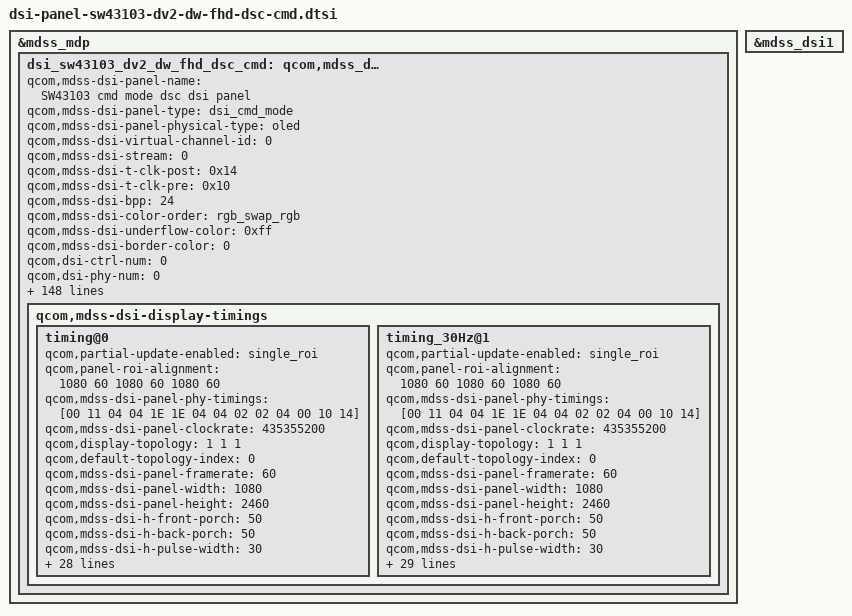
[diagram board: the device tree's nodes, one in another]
/* Copyright (c) 2014, Code Aurora Forum. All rights reserved.
 *
 * This program is free software; you can redistribute it and/or modify
 * it under the terms of the GNU General Public License version 2 and
 * only version 2 as published by the Free Software Foundation.
 *
 * This program is distributed in the hope that it will be useful,
 * but WITHOUT ANY WARRANTY; without even the implied warranty of
 * MERCHANTABILITY or FITNESS FOR A PARTICULAR PURPOSE.  See the
 * GNU General Public License for more details.
 */

&mdss_mdp {
    dsi_sw43103_dv2_dw_fhd_dsc_cmd: qcom,mdss_dsi_sw43103_dv2_dw_fhd_dsc_cmd {
		qcom,mdss-dsi-panel-name = "SW43103 cmd mode dsc dsi panel";
		qcom,mdss-dsi-panel-type = "dsi_cmd_mode";
		qcom,mdss-dsi-panel-physical-type = "oled";
		qcom,mdss-dsi-virtual-channel-id = <0>;
		qcom,mdss-dsi-stream = <0>;
		qcom,mdss-dsi-t-clk-post = <0x14>;
		qcom,mdss-dsi-t-clk-pre = <0x10>;
		qcom,mdss-dsi-bpp = <24>;
		qcom,mdss-dsi-color-order = "rgb_swap_rgb";
		qcom,mdss-dsi-underflow-color = <0xff>;
		qcom,mdss-dsi-border-color = <0>;
		qcom,dsi-ctrl-num = <0>;
		qcom,dsi-phy-num = <0>;
		qcom,dsi-select-clocks = "mux_byte_clk0", "mux_pixel_clk0";
		qcom,mdss-dsi-traffic-mode = "burst_mode";
		qcom,mdss-dsi-lane-map = "lane_map_0123";
		qcom,mdss-dsi-bllp-eof-power-mode;
		qcom,mdss-dsi-bllp-power-mode;
		qcom,mdss-dsi-lane-0-state;
		qcom,mdss-dsi-lane-1-state;
		qcom,mdss-dsi-lane-2-state;
		qcom,mdss-dsi-lane-3-state;
		qcom,mdss-dsi-reset-sequence = <1 10>, <0 2>, <1 10>;
		qcom,mdss-dsi-dma-trigger = "trigger_sw";
		qcom,mdss-dsi-mdp-trigger = "none";
		qcom,mdss-dsi-te-pin-select = <1>;
		qcom,panel-te-source = <0>;
		qcom,mdss-dsi-wr-mem-start = <0x2c>;
		qcom,mdss-dsi-wr-mem-continue = <0x3c>;
		qcom,mdss-dsi-te-dcs-command = <1>;
		qcom,mdss-dsi-lp11-init;
		qcom,mdss-dsi-tx-eot-append;
		qcom,ulps-enabled;
		//qcom,null-insertion-enabled;

		qcom,mdss-dsi-panel-hdr-enabled;
		qcom,mdss-dsi-panel-hdr-color-primaries = <14880 15935 32435 16555 14945 30910 7790 3415>;
		qcom,mdss-dsi-panel-peak-brightness = <5000000>;		/* max. 500nits */
		qcom,mdss-dsi-panel-blackness-level = <6134>;

		qcom,mdss-pan-physical-width-dimension = <69>;
		qcom,mdss-pan-physical-height-dimension = <158>;

		//lge,use-dim-ctrl;
		/* Brightness Map List */
		lge,blmap-daylight = <
			0
			5 5 5 5 5 5 5 5 5 5 6 7 9 10 11 12 14 15 16 17
			19 20 21 22 23 25 26 27 28 30 31 32 33 35 36 37 38 40 41 42
			43 45 46 47 49 50 51 52 54 55 56 57 59 60 61 63 64 65 66 68
			69 74 78 83 87 92 97 101 106 110 115 119 124 129 133 138 142 147 152 156
			161 165 170 175 179 184 189 193 198 203 208 212 217 222 227 232 236 241 246 251
			256 260 265 270 275 279 284 289 297 304 312 320 327 335 343 350 358 366 373 381
			389 396 404 412 419 427 435 442 450 458 465 473 481 489 496 504 512 520 528 536
			544 552 560 568 576 584 592 600 608 616 624 632 640 648 656 664 672 680 688 701
			714 726 739 752 765 777 790 803 816 828 841 854 867 880 892 905 918 931 943 956
			969 982 995 1007 1020 1033 1046 1058 1071 1084 1097 1109 1122 1135 1148 1161 1173 1186 1199 1212
			1224 1237 1250 1263 1275 1288 1301 1310 1320 1329 1339 1348 1357 1367 1376 1385 1395 1404 1414 1423
			1432 1442 1451 1460 1470 1479 1489 1498 1507 1517 1526 1536 1546 1556 1566 1576 1586 1597 1607 1617
			1627 1637 1648 1658 1668 1678 1688 1699 1709 1719 1729 1739 1750 1760 1770 1773 1775 1778 1780 1783
			1785 1788 1790 1793 1795 1798 1800 1803 1805 1808 1810 1813 1815 1818 1820 1823 1825 1828 1830 1833
			1835 1838 1841 1843 1846 1848 1851 1853 1856 1858 1861 1863 1866 1868 1871 1873 1876 1878 1881 1883
			1886 1888 1891 1893 1896 1898 1901 1903 1906 1909 1911 1914 1916 1919 1921 1924 1926 1929 1931 1934
			1936 1939 1941 1944 1946 1949 1951 1954 1956 1959 1961 1964 1966 1969 1971 1974 1976 1979 1982 1984
			1987 1989 1992 1994 1997 1999 2002 2004 2007 2009 2012 2014 2017 2019 2022 2024 2027 2029 2032 2034
			2037 2039 2042 2044 2047
		>;
		lge,blmap-ve = <
			0
			5 5 5 5 5 5 5 5 5 5 6 7 9 10 11 12 14 15 16 17
			19 20 21 22 23 25 26 27 28 30 31 32 33 35 36 37 38 40 41 42
			43 45 46 47 49 50 51 52 54 55 56 57 59 60 61 63 64 65 66 68
			69 74 78 83 87 92 97 101 106 110 115 119 124 129 133 138 142 147 152 156
			161 165 170 175 179 184 189 193 198 203 208 212 217 222 227 232 236 241 246 251
			256 260 265 270 275 279 284 289 297 304 312 320 327 335 343 350 358 366 373 381
			389 396 404 412 419 427 435 442 450 458 465 473 481 489 496 504 512 520 528 536
			544 552 560 568 576 584 592 600 608 616 624 632 640 648 656 664 672 680 688 701
			714 726 739 752 765 777 790 803 816 828 841 854 867 880 892 905 918 931 943 956
			969 982 995 1007 1020 1033 1046 1058 1071 1084 1097 1109 1122 1135 1148 1161 1173 1186 1199 1212
			1224 1237 1250 1263 1275 1288 1301 1310 1320 1329 1339 1348 1357 1367 1376 1385 1395 1404 1414 1423
			1432 1442 1451 1460 1470 1479 1489 1498 1507 1517 1526 1536 1546 1556 1566 1576 1586 1597 1607 1617
			1627 1637 1648 1658 1668 1678 1688 1699 1709 1719 1729 1739 1750 1760 1770 1773 1775 1778 1780 1783
			1785 1788 1790 1793 1795 1798 1800 1803 1805 1808 1810 1813 1815 1818 1820 1823 1825 1828 1830 1833
			1835 1838 1841 1843 1846 1848 1851 1853 1856 1858 1861 1863 1866 1868 1871 1873 1876 1878 1881 1883
			1886 1888 1891 1893 1896 1898 1901 1903 1906 1909 1911 1914 1916 1919 1921 1924 1926 1929 1931 1934
			1936 1939 1941 1944 1946 1949 1951 1954 1956 1959 1961 1964 1966 1969 1971 1974 1976 1979 1982 1984
			1987 1989 1992 1994 1997 1999 2002 2004 2007 2009 2012 2014 2017 2019 2022 2024 2027 2029 2032 2034
			2037 2039 2042 2044 2047
		>;
		lge,blmap-ex = <
			0
			16 16 16 16 16 16 16 16 16 25 35 44 53 62 72 81 90 99 109 118
			127 136 146 155 164 173 183 192 201 210 220 229 238 247 257 266 273 281 288 295
			303 310 317 325 332 339 347 354 361 369 376 383 391 398 405 413 420 427 435 442
			449 457 464 471 479 486 493 501 508 515 523 530 537 545 552 572 592 612 632 652
			672 692 712 732 752 772 792 812 832 852 872 892 912 932 952 972 992 1009 1026 1043
			1060 1076 1093 1110 1127 1144 1161 1178 1195 1212 1228 1245 1262 1279 1296 1310 1325 1339 1353 1368
			1382 1396 1411 1425 1439 1453 1468 1482 1496 1511 1525 1539 1554 1568 1568 1568 1568 1568 1568 1568
			1589 1611 1632 1653 1674 1696 1717 1738 1759 1781 1802 1823 1844 1866 1887 1908 1929 1951 1972 1972
			1972 1972 1972 1972 1972 1972 1972 1972 1972 1972 1972 1972 1972 1972 1972 1972 1972 1972 1972 1972
			1972 1972 1972 1972 1972 1972 1972 1972 1972 1972 1972 1972 1972 1972 1972 1972 1972 1972 1972 1972
			1972 1972 1972 1972 1972 1972 1972 1972 1972 1972 1972 1972 1972 1972 1972 1972 1972 1972 1972 1972
			1972 1972 1972 1972 1972 1972 1972 1972 1972 1972 1972 1972 1972 1972 1972 1972 1972 1972 1972 1972
			1972 1972 1972 1972 1972 1972 1972 1972 1972 1972 1972 1972 1972 1972 1972
		>;
		lge,blmap-hdr-daylight = <
			0
			5 5 5 5 5 5 5 5 5 5 6 7 9 10 11 12 14 15 16 17
			19 20 21 22 23 25 26 27 28 30 31 32 33 35 36 37 38 40 41 42
			43 45 46 47 49 50 51 52 54 55 56 57 59 60 61 63 64 65 66 68
			69 74 78 83 87 92 97 101 106 110 115 119 124 129 133 138 142 147 152 156
			161 165 170 175 179 184 189 193 198 203 208 212 217 222 227 232 236 241 246 251
			256 260 265 270 275 279 284 289 297 304 312 320 327 335 343 350 358 366 373 381
			389 396 404 412 419 427 435 442 450 458 465 473 481 489 496 504 512 520 528 536
			544 552 560 568 576 584 592 600 608 616 624 632 640 648 656 664 672 680 688 701
			714 726 739 752 765 777 790 803 816 828 841 854 867 880 892 905 918 931 943 956
			969 982 995 1007 1020 1033 1046 1058 1071 1084 1097 1109 1122 1135 1148 1161 1173 1186 1199 1212
			1224 1237 1250 1263 1275 1288 1301 1310 1320 1329 1339 1348 1357 1367 1376 1385 1395 1404 1414 1423
			1432 1442 1451 1460 1470 1479 1489 1498 1507 1517 1526 1536 1546 1556 1566 1576 1586 1597 1607 1617
			1627 1637 1648 1658 1668 1678 1688 1699 1709 1719 1729 1739 1750 1760 1770 1773 1775 1778 1780 1783
			1785 1788 1790 1793 1795 1798 1800 1803 1805 1808 1810 1813 1815 1818 1820 1823 1825 1828 1830 1833
			1835 1838 1841 1843 1846 1848 1851 1853 1856 1858 1861 1863 1866 1868 1871 1873 1876 1878 1881 1883
			1886 1888 1891 1893 1896 1898 1901 1903 1906 1909 1911 1914 1916 1919 1921 1924 1926 1929 1931 1934
			1936 1939 1941 1944 1946 1949 1951 1954 1956 1959 1961 1964 1966 1969 1971 1974 1976 1979 1982 1984
			1987 1989 1992 1994 1997 1999 2002 2004 2007 2009 2012 2014 2017 2019 2022 2024 2027 2029 2032 2034
			2037 2039 2042 2044 2047
		>;
		lge,blmap = <
			0
			5 5 5 5 5 5 5 5 5 5 6 7 8 9 10 11 12 13 14 15
			16 17 18 19 20 21 22 23 24 25 26 27 28 29 30 31 32 33 34 35
			36 37 38 39 40 41 42 43 45 46 47 48 49 50 51 52 53 54 55 56
			57 61 65 68 72 76 80 83 87 91 95 98 102 106 110 113 117 121 125 128
			132 136 140 144 147 151 155 159 163 167 170 174 178 182 186 190 194 198 202 206
			210 214 217 221 225 229 233 237 243 250 256 263 269 276 282 289 295 302 308 315
			321 327 334 340 347 353 360 366 373 379 386 392 399 405 412 418 425 432 439 445
			452 459 465 472 479 485 492 499 506 512 519 526 532 539 546 553 559 566 573 583
			594 604 615 625 636 646 657 667 677 688 698 709 719 730 740 750 761 771 782 792
			803 813 824 834 844 855 865 876 886 897 907 917 928 938 949 959 970 980 991 1001
			1011 1022 1032 1043 1053 1064 1074 1083 1093 1102 1111 1121 1130 1139 1149 1158 1167 1177 1186 1195
			1205 1214 1223 1233 1242 1251 1261 1270 1279 1289 1298 1308 1318 1328 1338 1348 1358 1368 1379 1389
			1399 1409 1419 1429 1439 1450 1460 1470 1480 1490 1500 1511 1521 1531 1541 1546 1550 1555 1559 1564
			1569 1573 1578 1582 1587 1592 1596 1601 1605 1610 1615 1619 1624 1628 1633 1638 1642 1647 1651 1656
			1661 1665 1670 1674 1679 1684 1688 1693 1697 1702 1707 1711 1716 1720 1725 1730 1734 1739 1743 1748
			1753 1757 1762 1766 1771 1776 1780 1785 1789 1794 1799 1803 1808 1812 1817 1822 1826 1831 1835 1840
			1845 1849 1854 1858 1863 1868 1872 1877 1881 1886 1891 1895 1900 1904 1909 1914 1918 1923 1927 1932
			1937 1941 1946 1950 1955 1960 1964 1969 1973 1978 1983 1987 1992 1996 2001 2006 2010 2015 2019 2024
			2029 2033 2038 2042 2047
		>;
		lge,blmap-hdr = <
			0
			5 5 5 5 5 5 5 5 5 5 6 7 8 9 10 11 12 13 14 15
			16 17 18 19 20 21 22 23 24 25 26 27 28 29 30 31 32 33 34 35
			36 37 38 39 40 41 42 43 45 46 47 48 49 50 51 52 53 54 55 56
			57 61 65 68 72 76 80 83 87 91 95 98 102 106 110 113 117 121 125 128
			132 136 140 144 147 151 155 159 163 167 170 174 178 182 186 190 194 198 202 206
			210 214 217 221 225 229 233 237 243 250 256 263 269 276 282 289 295 302 308 315
			321 327 334 340 347 353 360 366 373 379 386 392 399 405 412 418 425 432 439 445
			452 459 465 472 479 485 492 499 506 512 519 526 532 539 546 553 559 566 573 583
			594 604 615 625 636 646 657 667 677 688 698 709 719 730 740 750 761 771 782 792
			803 813 824 834 844 855 865 876 886 897 907 917 928 938 949 959 970 980 991 1001
			1011 1022 1032 1043 1053 1064 1074 1083 1093 1102 1111 1121 1130 1139 1149 1158 1167 1177 1186 1195
			1205 1214 1223 1233 1242 1251 1261 1270 1279 1289 1298 1308 1318 1328 1338 1348 1358 1368 1379 1389
			1399 1409 1419 1429 1439 1450 1460 1470 1480 1490 1500 1511 1521 1531 1541 1546 1550 1555 1559 1564
			1569 1573 1578 1582 1587 1592 1596 1601 1605 1610 1615 1619 1624 1628 1633 1638 1642 1647 1651 1656
			1661 1665 1670 1674 1679 1684 1688 1693 1697 1702 1707 1711 1716 1720 1725 1730 1734 1739 1743 1748
			1753 1757 1762 1766 1771 1776 1780 1785 1789 1794 1799 1803 1808 1812 1817 1822 1826 1831 1835 1840
			1845 1849 1854 1858 1863 1868 1872 1877 1881 1886 1891 1895 1900 1904 1909 1914 1918 1923 1927 1932
			1937 1941 1946 1950 1955 1960 1964 1969 1973 1978 1983 1987 1992 1996 2001 2006 2010 2015 2019 2024
			2029 2033 2038 2042 2047
		>;

		lge,mdss-dsi-nolp-command = [
			15 01 00 00 28 00 02 53 84
			39 01 00 00 00 00 02 B0 A1
			39 01 00 00 3C 00 12 C1 88 C8 60 0F 51 50 50 34 4F 5A 33 06 54 54 11 11 02 // AVDD 6.7V change
			05 01 00 00 00 00 01 13
			15 01 00 00 00 00 02 B0 CA
		];
		lge,mdss-dsi-nolp-command-state = "dsi_lp_mode";
		lge,mdss-dsi-lp2-command = [
			15 01 00 00 14 00 02 53 00
			39 01 00 00 00 00 02 B0 A1
			39 01 00 00 3C 00 12 C1 88 C8 60 0F 51 50 50 34 4F 5A 33 06 54 54 08 11 02 // AVDD 5.8V change
			05 01 00 00 00 00 01 12
			15 01 00 00 00 00 02 B0 CA
		];
		lge,mdss-dsi-lp2-command-state = "dsi_lp_mode";

		lge,use-vr-lp-mode;
		lge,mdss-dsi-vr-lp-mode-on-command = [
			15 01 00 00 00 00 02 B0 A3
			39 01 00 00 00 00 08 B5 00 0B 00 3B 00 3B 10
			15 01 00 00 00 00 02 B0 CA
		];
		lge,mdss-dsi-vr-lp-mode-off-command = [
			15 01 00 00 00 00 02 B0 A3
			39 01 00 00 00 00 08 B5 00 3B 00 3B 00 3B 10
			15 01 00 00 00 00 02 B0 CA
		];
		lge,mdss-dsi-vr-lp-command-state = "dsi_lp_mode";
		lge,blmap-vr = < 0 165 >;

		lge,use-color-manager;
		lge,use-color-manager-oled;
		lge,color-manager-default-status = <1>;
		lge,mdss-dsi-color-manager-mode-table = <0 1>, <1 1>, <2 1>, <3 1>;
		lge,digital-gamma-absent;

		/* FP LHBM */
		lge,use-fp-lhbm;
		lge,use-fps-mode1-new;
		lge,mdss-dsi-fp-lhbm-ready-command = [
			15 01 00 00 00 00 02 53 A4
			39 00 00 00 00 00 03 51 05 53
			15 00 00 00 00 00 02 B0 A3
			39 00 00 00 00 00 1F B6 90 00 A1 80 F7 AA 90 00 A1 63 60 41 45 0D 94 26 BD E4 27 61 40 18 05 9C 08 A9 F8 09 A1 00
			15 01 00 00 00 00 02 B0 CA
		];
		lge,mdss-dsi-fp-lhbm-ready-command-state = "dsi_hs_mode";

		lge,mdss-dsi-fp-lhbm-exit-command = [
			15 01 00 00 00 00 02 53 84
			15 00 00 00 00 00 02 B0 A3
			39 00 00 00 00 00 1F B6 90 00 A1 80 F7 AA 71 B0 F1 63 60 41 45 0D 94 26 BD E4 27 61 40 18 05 9C 08 A9 F8 09 A1 00
			15 01 00 00 00 00 02 B0 CA
		];
		lge,mdss-dsi-fp-lhbm-exit-command-state = "dsi_hs_mode";

		lge,mdss-dsi-pre-fp-lhbm-on-command = [
			39 00 00 00 00 00 03 51 05 53
			15 00 00 00 00 00 02 B0 A3
			39 00 00 00 00 00 1F B6 90 00 A1 80 F7 AA 90 00 A1 63 60 41 45 0D 94 26 BD E4 27 61 40 18 05 9C 08 A9 F8 09 A1 00
			15 01 00 00 00 00 02 B0 CA
		];
		lge,mdss-dsi-pre-fp-lhbm-on-command-state = "dsi_hs_mode";

		lge,mdss-dsi-fp-lhbm-on-command = [
			39 01 00 00 00 00 03 51 05 53
			39 01 00 00 00 00 0B 55 08 08 72 D4 1C 61 0A 90 04 00
		];
		lge,mdss-dsi-fp-lhbm-on-command-state = "dsi_hs_mode";

		lge,mdss-dsi-fp-lhbm-off-command = [
			39 01 00 00 00 00 0B 55 08 00 72 D4 1C 61 0A 90 04 00
		];
		lge,mdss-dsi-fp-lhbm-off-command-state = "dsi_hs_mode";

		lge,mdss-dsi-post-fp-lhbm-off-command = [
			15 00 00 00 00 00 02 B0 A3
			39 00 00 00 00 00 1F B6 90 00 A1 80 F7 AA 71 B0 F1 63 60 41 45 0D 94 26 BD E4 27 61 40 18 05 9C 08 A9 F8 09 A1 00
			15 01 00 00 00 00 02 B0 CA
		];
		lge,mdss-dsi-post-fp-lhbm-off-command-state = "dsi_hs_mode";

		lge,mdss-dsi-fp-lhbm-aod-to-fps = [
			39 01 00 00 00 00 02 B0 A3
			39 01 00 00 00 00 0D B7 09 A1 00 09 A1 00 09 A1 00 09 A1 00 // AOD EM OFF
			39 01 00 00 00 00 03 51 00 00 // Set 0 brightness

			39 01 00 00 00 00 02 B0 A1
			39 01 00 00 00 00 12 C1 88 C8 60 0F 51 50 50 34 4F 5A 33 06 54 54 11 11 02 // AVDD 6.7V change
			05 01 00 00 32 00 01 13 //Normal On
			39 01 00 00 00 00 02 B0 A3
			39 01 00 00 00 00 0D B7 45 41 60 27 51 50 08 A9 F8 09 A1 00 // AOD EM ON
			15 01 00 00 00 00 02 B0 CA
		];
		lge,mdss-dsi-fp-lhbm-aod-to-fps-state = "dsi_hs_mode";

		lge,mdss-dsi-fp-lhbm-fps-to-aod = [
			39 01 00 00 00 00 03 51 00 00 // Set 0 brightness
			39 01 00 00 00 00 02 B0 A1
			39 01 00 00 3C 00 12 C1 88 C8 60 0F 51 50 50 34 4F 5A 33 06 54 54 08 11 02 // AVDD 5.8V change
			05 01 00 00 00 00 01 12 //AOD On
			15 01 00 00 00 00 02 B0 CA
		];
		lge,mdss-dsi-fp-lhbm-fps-to-aod-state = "dsi_hs_mode";

		/* Screen Color Control */
		lge,mdss-dsi-disp-ctrl-command-1 = [
			15 01 00 00 00 00 02 B0 A1
			15 01 00 00 00 00 02 53 00
			15 01 00 00 00 00 02 B0 CA
		];
		lge,mdss-dsi-disp-ctrl-command-1-state = "dsi_hs_mode";

		lge,mdss-dsi-wb-default-command = [
			15 01 00 00 00 00 02 B0 A4
			39 01 00 00 00 00 0B B4 00 03 05 AF 03 05 AF 03 05 AF
			39 01 00 00 00 00 1C B5 00 FF 94 1F AE 37 AE 1F 94 00 FB 94 1E AD 35 AB 1C 90 00 DD 8F 16 9F 24 97 04 75
			15 01 00 00 00 00 02 B0 CA
		];
		lge,mdss-dsi-wb-default-command-state = "dsi_hs_mode";

		lge,digital-gamma-cmds-dummy = [
			15 01 00 00 00 00 02 B0 A4
			39 01 00 00 00 00 0B B4 00 03 05 AF 03 05 AF 03 05 AF
			39 01 00 00 00 00 1C B5 00 FF 94 1F AE 37 AE 1F 94 00 FB 94 1E AD 35 AB 1C 90 00 DD 8F 16 9F 24 97 04 75
			15 01 00 00 00 00 02 B0 CA
		];
		lge,digital-gamma-cmds-dummy-command = "dsi_hs_mode";

		lge,mdss-dsi-saturation-command = [
			15 01 00 00 00 00 02 B0 A4
			39 01 00 00 00 00 0D B9 35 2D 2D 37 34 35 36 36 36 2D 35 33
			15 01 00 00 00 00 02 B0 CA
		];
		lge,mdss-dsi-saturation-command-state = "dsi_hs_mode";

		lge,mdss-dsi-hue-command = [
			15 01 00 00 00 00 02 B0 A4
			39 01 00 00 00 00 0D BB 80 5A 7B 95 65 70 96 90 90 90 83 72
			15 01 00 00 00 00 02 B0 CA
		];
		lge,mdss-dsi-hue-command-state = "dsi_hs_mode";

		lge,mdss-dsi-sharpness-command = [
			15 01 00 00 00 00 02 B0 A4
			39 01 00 00 00 00 0C B2 89 1F 1F 88 24 68 22 20 04 00 00
			15 01 00 00 00 00 02 B0 CA
		];
		lge,mdss-dsi-sharpness-command-state = "dsi_hs_mode";

		lge,mdss-dsi-cm-natural = [
			15 01 00 00 00 00 02 B0 A4
			39 01 00 00 00 00 0B B4 00 03 05 AF 03 05 AF 03 05 AF
			39 01 00 00 00 00 1C B5 00 FF 94 1F AE 37 AE 1F 94 00 FB 94 1E AD 35 AB 1C 90 00 DD 8F 16 9F 24 97 04 75
			39 01 00 00 00 00 0D B7 80 80 80 80 80 80 80 80 80 80 80 80
			39 01 00 00 00 00 0D B8 80 80 80 80 80 80 80 80 80 80 80 80
			39 01 00 00 00 00 0D B9 35 2D 2D 37 34 35 36 36 36 2D 35 33
			39 01 00 00 00 00 0D BA 80 80 80 80 88 80 80 80 80 80 80 7D
			39 01 00 00 00 00 0D BB 80 5A 7B 95 65 70 96 90 90 90 83 72
			15 01 00 00 00 00 02 B0 CA
		];
		lge,mdss-dsi-cm-natural-state = "dsi_hs_mode";

		lge,mdss-dsi-cm-vivid = [
			15 01 00 00 00 00 02 B0 A4
			39 01 00 00 00 00 0B B4 00 03 05 AF 03 05 AF 03 05 AF
			39 01 00 00 00 00 1C B5 00 FF 90 22 B3 37 AE 1F 90 00 FF 8E 19 AC 34 AE 23 96 00 FF 90 1E AE 30 A6 13 88
			39 01 00 00 00 00 0D B7 80 80 80 80 80 80 80 80 80 80 80 80
			39 01 00 00 00 00 0D B8 80 80 80 80 80 80 80 80 80 80 80 80
			39 01 00 00 00 00 0D B9 43 43 43 3D 38 3E 43 43 43 43 46 46
			39 01 00 00 00 00 0D BA 80 80 80 80 80 80 80 80 80 80 80 80
			39 01 00 00 00 00 0D BB 80 80 80 80 7A 80 80 80 80 80 80 80
			15 01 00 00 00 00 02 B0 CA
		];
		lge,mdss-dsi-cm-vivid-state = "dsi_hs_mode";

		lge,mdss-dsi-cm-cinema = [
			15 01 00 00 00 00 02 B0 A4
			39 01 00 00 00 00 0B B4 00 03 05 AF 03 05 AF 03 05 AB
			39 01 00 00 00 00 1C B5 00 FF A1 26 AF 38 AF 20 95 00 EC 90 18 AF 31 A7 17 80 00 B3 8D 12 9A 14 84 F7 65
			39 01 00 00 00 00 0D B7 80 80 80 80 80 80 80 80 80 80 80 80
			39 01 00 00 00 00 0D B8 80 80 80 80 89 80 80 80 80 80 80 80
			39 01 00 00 00 00 0D B9 39 3A 36 3A 3D 38 3D 3A 3A 3A 35 35
			39 01 00 00 00 00 0D BA 80 80 80 80 88 80 80 80 80 80 7D 7D
			39 01 00 00 00 00 0D BB 6A 77 85 8B 75 70 86 85 85 80 5D 6F
			15 01 00 00 00 00 02 B0 CA
		];
		lge,mdss-dsi-cm-cinema-state = "dsi_hs_mode";

		/* Video Enahnacement */
		lge,mdss-dsi-ve-on-command = [
			15 01 00 00 00 00 02 53 84
			15 01 00 00 00 00 02 B0 A4
			39 01 00 00 00 00 0D B7 80 80 80 80 80 80 80 80 80 80 80 80
			39 01 00 00 00 00 0D B8 80 80 80 80 80 80 80 80 80 80 80 80
			39 01 00 00 00 00 0D B9 46 46 46 43 38 43 46 46 46 46 46 46
			39 01 00 00 00 00 0D BA 80 80 80 80 80 80 80 80 80 80 80 80
			39 01 00 00 00 00 0D BB 80 80 80 80 7A 80 80 80 80 80 80 80
			15 01 00 00 00 00 02 B0 CA
		];
		lge,mdss-dsi-ve-on-command-state = "dsi_hs_mode";

		lge,use-irc-ctrl;
		lge,mdss-dsi-irc-command = [
			15 01 00 00 00 00 02 B0 A5
			39 01 00 00 00 00 08 B1 60 C0 00 00 00 10 FF
			15 01 00 00 00 00 02 B0 CA
		];
		lge,mdss-dsi-irc-command-state = "dsi_hs_mode";

		lge,use-ace-ctrl;
		lge,default-ace-mode = <0>;
		lge,mdss-dsi-ace-tune-command = [
			15 01 00 00 00 00 02 B0 A4
			39 01 00 00 00 00 0C B2 89 3F 2F 88 88 88 33 20 04 00 00
			39 01 00 00 00 00 07 B3 00 80 FF 88 08 93
			15 01 00 00 00 00 02 B0 A1
			15 01 00 00 00 00 02 53 14
			39 01 00 00 00 00 02 55 28
			15 01 00 00 00 00 02 B0 CA
		];
		lge,mdss-dsi-ace-restore-command = [
			15 01 00 00 00 00 02 B0 A1
			39 01 00 00 00 00 02 55 08
			15 01 00 00 00 00 02 B0 CA
		];
		lge,mdss-dsi-ace-command-state = "dsi_hs_mode";

		/* tc Perf */
		lge,use-tc-perf;
		lge,mdss-dsi-tc-perf-on-command = [
			15 01 00 00 00 00 02 B0 A3
			39 01 00 00 00 00 1F B6 90 00 A1 90 00 A1 71 B0 F1 63 60 41 45 0D 94 26 BD E4 27 61 40 18 05 9C 08 A9 F8 09 A1 00
			15 01 00 00 00 00 02 B0 CA
		];
		lge,mdss-dsi-tc-perf-on-command-state = "dsi_hs_mode";

		lge,mdss-dsi-tc-perf-off-command = [
			15 01 00 00 00 00 02 B0 A3
			39 01 00 00 00 00 1F B6 90 00 A1 80 F7 AA 71 B0 F1 63 60 41 45 0D 94 26 BD E4 27 61 40 18 05 9C 08 A9 F8 09 A1 00
			15 01 00 00 00 00 02 B0 CA
		];
		lge,mdss-dsi-tc-perf-off-command-state = "dsi_hs_mode";

		qcom,mdss-dsi-display-timings {
			timing@0{
				qcom,partial-update-enabled = "single_roi";
				qcom,panel-roi-alignment = <1080 60 1080 60 1080 60>;
				qcom,mdss-dsi-panel-phy-timings = [00 11 04 04 1E 1E 04 04 02 02 04 00 10 14];
				qcom,mdss-dsi-panel-clockrate = <435355200>;
				qcom,display-topology = <1 1 1>;
				qcom,default-topology-index = <0>;
				qcom,mdss-dsi-panel-framerate = <60>;
				qcom,mdss-dsi-panel-width = <1080>;
				qcom,mdss-dsi-panel-height = <2460>;
				qcom,mdss-dsi-h-front-porch = <50>;
				qcom,mdss-dsi-h-back-porch = <50>;
				qcom,mdss-dsi-h-pulse-width = <30>;
				qcom,mdss-dsi-h-sync-skew = <0>;
				qcom,mdss-dsi-v-back-porch = <2>;
				qcom,mdss-dsi-v-front-porch = <4>;
				qcom,mdss-dsi-v-pulse-width = <2>;
				qcom,mdss-dsi-h-left-border = <0>;
				qcom,mdss-dsi-h-right-border = <0>;
				qcom,mdss-dsi-v-top-border = <0>;
				qcom,mdss-dsi-v-bottom-border = <0>;
				qcom,mdss-dsi-h-sync-pulse = <0>;
				//qcom,mdss-mdp-transfer-time-us = <15000>;

				qcom,mdss-dsi-on-command = [
					15 01 00 00 00 00 02 B0 A1
					39 01 00 00 00 00 05 2A 00 00 04 37
					39 01 00 00 00 00 05 2B 00 00 09 9B
					15 01 00 00 00 00 02 55 08
					39 01 00 00 00 00 05 30 00 00 09 9B
					39 01 00 00 00 00 05 31 00 00 04 37
					15 01 00 00 00 00 02 35 00
					15 01 00 00 00 00 02 B0 CA
					05 01 00 00 64 00 01 11

					15 01 00 00 00 00 02 B0 A6
					39 01 00 00 00 00 05 FC 00 00 41 40				//Touch Vsync_enable

					15 01 00 00 00 00 02 B0 A3
					39 01 00 00 00 00 06 B3 1F 63 00 00 06

					15 01 00 00 00 00 02 B0 A5
					39 01 00 00 00 00 1E CD 10 12 01 5A 90 00 00 00 00 00 61 00 01 01 00 01 11 40 00 00 00 00 3F FF FF FF 70 FF 00 //Green Circle

					15 01 00 00 00 00 02 53 84
					15 01 00 00 00 00 02 B0 A4
					39 01 00 00 00 00 0B B4 00 03 05 AF 03 05 AF 03 05 AF
					39 01 00 00 00 00 1C B5 00 FF 94 1F AE 37 AE 1F 94 00 FB 94 1E AD 35 AB 1C 90 00 DD 8F 16 9F 24 97 04 75
					39 01 00 00 00 00 0D B7 80 80 80 80 80 80 80 80 80 80 80 80
					39 01 00 00 00 00 0D B8 80 80 80 80 80 80 80 80 80 80 80 80
					39 01 00 00 00 00 0D B9 35 2D 2D 37 34 35 36 36 36 2D 35 33
					39 01 00 00 00 00 0D BA 80 80 80 80 88 80 80 80 80 80 80 7D
					39 01 00 00 00 00 0D BB 80 5A 7B 95 65 70 96 90 90 90 83 72

					15 01 00 00 00 00 02 B0 A1
					39 01 00 00 00 00 12 C1 88 C8 60 0F 51 50 50 34 4F 5A 33 1D 54 54 11 11 02
					39 01 00 00 00 00 1F C3 16 1D 25 26 26 26 26 26 26 26 16 1D 25 26 26 26 26 26 26 26 16 1D 25 26 26 26 26 26 26 26
					39 01 00 00 00 00 0D C4 13 13 13 13 13 13 13 13 13 13 13 13

					15 01 00 00 00 00 02 B0 CA

					05 01 00 00 14 00 01 29
				];

				qcom,mdss-dsi-off-command = [
					05 01 00 00 46 00 01 13
					05 01 00 00 00 00 01 28
					05 01 00 00 46 00 01 10
				];

				qcom,compression-mode = "dsc";
				qcom,mdss-dsc-version = <0x11>;
				qcom,mdss-dsc-scr-version = <0x1>;
				qcom,mdss-dsc-slice-height = <60>;
				qcom,mdss-dsc-slice-width = <540>;
				qcom,mdss-dsc-slice-per-pkt = <2>;
				qcom,mdss-dsc-bit-per-component = <8>;
				qcom,mdss-dsc-bit-per-pixel = <8>;
				qcom,lm-split = <540 540>;
				qcom,mdss-dsc-encoders = <2>;
				qcom,mdss-dsc-block-prediction-enable;

				qcom,mdss-dsi-on-command-state = "dsi_lp_mode";
				qcom,mdss-dsi-off-command-state = "dsi_lp_mode";

				qcom,mode-control-dsi-state = "dsi_lp_mode";
				qcom,mdss-dsi-pps-command-state = "dsi_hs_mode";
			};

			timing_30Hz@1{
				qcom,partial-update-enabled = "single_roi";
				qcom,panel-roi-alignment = <1080 60 1080 60 1080 60>;
				qcom,mdss-dsi-panel-phy-timings = [00 11 04 04 1E 1E 04 04 02 02 04 00 10 14];
				qcom,mdss-dsi-panel-clockrate = <435355200>;
				qcom,display-topology = <1 1 1>;
				qcom,default-topology-index = <0>;
				qcom,mdss-dsi-panel-framerate = <60>;
				qcom,mdss-dsi-panel-width = <1080>;
				qcom,mdss-dsi-panel-height = <2460>;
				qcom,mdss-dsi-h-front-porch = <50>;
				qcom,mdss-dsi-h-back-porch = <50>;
				qcom,mdss-dsi-h-pulse-width = <30>;
				qcom,mdss-dsi-h-sync-skew = <0>;
				qcom,mdss-dsi-v-back-porch = <2>;
				qcom,mdss-dsi-v-front-porch = <4>;
				qcom,mdss-dsi-v-pulse-width = <2>;
				qcom,mdss-dsi-h-left-border = <0>;
				qcom,mdss-dsi-h-right-border = <0>;
				qcom,mdss-dsi-v-top-border = <0>;
				qcom,mdss-dsi-v-bottom-border = <0>;
				qcom,mdss-dsi-h-sync-pulse = <0>;
				//qcom,mdss-mdp-transfer-time-us = <15000>;
				lge,mdss-dsi-panel-framerate-div = <2>;

				qcom,mdss-dsi-on-command = [
					15 01 00 00 00 00 02 B0 A1
					39 01 00 00 00 00 05 2A 00 00 04 37
					39 01 00 00 00 00 05 2B 00 00 09 9B
					15 01 00 00 00 00 02 55 08
					39 01 00 00 00 00 05 30 00 00 09 9B
					39 01 00 00 00 00 05 31 00 00 04 37
					15 01 00 00 00 00 02 35 00
					15 01 00 00 00 00 02 B0 CA
					05 01 00 00 64 00 01 11

					15 01 00 00 00 00 02 B0 A6
					39 01 00 00 00 00 05 FC 00 00 41 40				//Touch Vsync_enable

					15 01 00 00 00 00 02 B0 A3
					39 01 00 00 00 00 06 B3 1F 63 00 00 06

					15 01 00 00 00 00 02 B0 A5
					39 01 00 00 00 00 1E CD 10 12 01 5A 90 00 00 00 00 00 61 00 01 01 00 01 11 40 00 00 00 00 3F FF FF FF 70 FF 00 //Green Circle

					15 01 00 00 00 00 02 53 84
					15 01 00 00 00 00 02 B0 A4
					39 01 00 00 00 00 0B B4 00 03 05 AF 03 05 AF 03 05 AF
					39 01 00 00 00 00 1C B5 00 FF 94 1F AE 37 AE 1F 94 00 FB 94 1E AD 35 AB 1C 90 00 DD 8F 16 9F 24 97 04 75
					39 01 00 00 00 00 0D B7 80 80 80 80 80 80 80 80 80 80 80 80
					39 01 00 00 00 00 0D B8 80 80 80 80 80 80 80 80 80 80 80 80
					39 01 00 00 00 00 0D B9 35 2D 2D 37 34 35 36 36 36 2D 35 33
					39 01 00 00 00 00 0D BA 80 80 80 80 88 80 80 80 80 80 80 7D
					39 01 00 00 00 00 0D BB 80 5A 7B 95 65 70 96 90 90 90 83 72

					15 01 00 00 00 00 02 B0 A1
					39 01 00 00 00 00 12 C1 88 C8 60 0F 51 50 50 34 4F 5A 33 1D 54 54 11 11 02
					39 01 00 00 00 00 1F C3 16 1D 25 26 26 26 26 26 26 26 16 1D 25 26 26 26 26 26 26 26 16 1D 25 26 26 26 26 26 26 26
					39 01 00 00 00 00 0D C4 13 13 13 13 13 13 13 13 13 13 13 13

					15 01 00 00 00 00 02 B0 CA

					05 01 00 00 14 00 01 29
				];

				qcom,mdss-dsi-off-command = [
					05 01 00 00 46 00 01 13
					05 01 00 00 00 00 01 28
					05 01 00 00 46 00 01 10
				];

				qcom,compression-mode = "dsc";
				qcom,mdss-dsc-version = <0x11>;
				qcom,mdss-dsc-scr-version = <0x1>;
				qcom,mdss-dsc-slice-height = <60>;
				qcom,mdss-dsc-slice-width = <540>;
				qcom,mdss-dsc-slice-per-pkt = <2>;
				qcom,mdss-dsc-bit-per-component = <8>;
				qcom,mdss-dsc-bit-per-pixel = <8>;
				qcom,lm-split = <540 540>;
				qcom,mdss-dsc-encoders = <2>;
				qcom,mdss-dsc-block-prediction-enable;

				qcom,mdss-dsi-on-command-state = "dsi_lp_mode";
				qcom,mdss-dsi-off-command-state = "dsi_lp_mode";

				qcom,mode-control-dsi-state = "dsi_lp_mode";
				qcom,mdss-dsi-pps-command-state = "dsi_hs_mode";
			};

		};
	};
};

&mdss_dsi1 {
	status = "ok";
};
